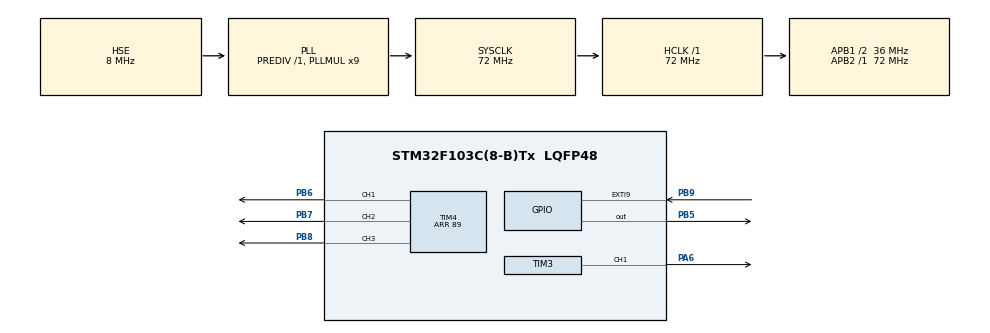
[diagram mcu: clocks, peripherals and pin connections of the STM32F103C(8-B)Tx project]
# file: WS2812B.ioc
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Dma.Request0=TIM4_CH3
Dma.Request1=TIM4_CH2
Dma.Request2=TIM4_CH1
Dma.TIM4_CH1.2.Direction=DMA_MEMORY_TO_PERIPH
Dma.TIM4_CH1.2.Instance=DMA1_Channel1
Dma.TIM4_CH1.2.MemDataAlignment=DMA_MDATAALIGN_HALFWORD
Dma.TIM4_CH1.2.MemInc=DMA_MINC_ENABLE
Dma.TIM4_CH1.2.Mode=DMA_NORMAL
Dma.TIM4_CH1.2.PeriphDataAlignment=DMA_PDATAALIGN_HALFWORD
Dma.TIM4_CH1.2.PeriphInc=DMA_PINC_DISABLE
Dma.TIM4_CH1.2.Priority=DMA_PRIORITY_HIGH
Dma.TIM4_CH2.1.Direction=DMA_MEMORY_TO_PERIPH
Dma.TIM4_CH2.1.Instance=DMA1_Channel4
Dma.TIM4_CH2.1.MemDataAlignment=DMA_MDATAALIGN_HALFWORD
Dma.TIM4_CH2.1.MemInc=DMA_MINC_ENABLE
Dma.TIM4_CH2.1.Mode=DMA_NORMAL
Dma.TIM4_CH2.1.PeriphDataAlignment=DMA_PDATAALIGN_HALFWORD
Dma.TIM4_CH2.1.PeriphInc=DMA_PINC_DISABLE
Dma.TIM4_CH2.1.Priority=DMA_PRIORITY_HIGH
Dma.TIM4_CH3.0.Direction=DMA_MEMORY_TO_PERIPH
Dma.TIM4_CH3.0.Instance=DMA1_Channel5
Dma.TIM4_CH3.0.MemDataAlignment=DMA_MDATAALIGN_HALFWORD
Dma.TIM4_CH3.0.MemInc=DMA_MINC_ENABLE
Dma.TIM4_CH3.0.Mode=DMA_NORMAL
Dma.TIM4_CH3.0.PeriphDataAlignment=DMA_PDATAALIGN_HALFWORD
Dma.TIM4_CH3.0.PeriphInc=DMA_PINC_DISABLE
Dma.TIM4_CH3.0.Priority=DMA_PRIORITY_HIGH
Mcu.Family=STM32F1
Mcu.Name=STM32F103C(8-B)Tx
Mcu.Package=LQFP48
NVIC.DMA1_Channel1_IRQn=true\:0\:0\:false\:false\:true\:false\:true
NVIC.DMA1_Channel4_IRQn=true\:0\:0\:false\:false\:true\:false\:true
NVIC.DMA1_Channel5_IRQn=true\:0\:0\:false\:false\:true\:false\:true
NVIC.EXTI9_5_IRQn=true\:0\:0\:false\:false\:true\:true\:true
NVIC.PriorityGroup=NVIC_PRIORITYGROUP_4
NVIC.TIM3_IRQn=true\:0\:0\:false\:false\:true\:true\:true
PA13.Mode=Serial_Wire
PA13.Signal=SYS_JTMS-SWDIO
PA14.Mode=Serial_Wire
PA14.Signal=SYS_JTCK-SWCLK
PA6.Signal=S_TIM3_CH1
PB5.GPIO_Speed=GPIO_SPEED_FREQ_LOW
PB5.Signal=GPIO_Output
PB6.GPIO_Speed=GPIO_SPEED_FREQ_HIGH
PB6.Signal=S_TIM4_CH1
PB7.GPIO_Speed=GPIO_SPEED_FREQ_HIGH
PB7.Signal=S_TIM4_CH2
PB8.GPIO_Speed=GPIO_SPEED_FREQ_HIGH
PB8.Signal=S_TIM4_CH3
PB9.GPIO_ModeDefaultEXTI=GPIO_MODE_IT_RISING
PB9.Signal=GPXTI9
PD0-OSC_IN.Mode=HSE-External-Oscillator
PD0-OSC_IN.Signal=RCC_OSC_IN
PD1-OSC_OUT.Mode=HSE-External-Oscillator
PD1-OSC_OUT.Signal=RCC_OSC_OUT
ProjectManager.HeapSize=0x200
ProjectManager.StackSize=0x400
ProjectManager.TargetToolchain=MDK-ARM V5
RCC.AHBFreq_Value=72000000
RCC.APB1CLKDivider=RCC_HCLK_DIV2
RCC.APB1Freq_Value=36000000
RCC.APB1TimFreq_Value=72000000
RCC.APB2Freq_Value=72000000
RCC.APB2TimFreq_Value=72000000
RCC.HCLKFreq_Value=72000000
RCC.PLLMUL=RCC_PLL_MUL9
RCC.PLLSourceVirtual=RCC_PLLSOURCE_HSE
RCC.SYSCLKFreq_VALUE=72000000
RCC.SYSCLKSource=RCC_SYSCLKSOURCE_PLLCLK
RCC.USBFreq_Value=72000000
SH.S_TIM3_CH1.0=TIM3_CH1,Output Compare1 CH1
SH.S_TIM4_CH1.0=TIM4_CH1,PWM Generation1 CH1
SH.S_TIM4_CH2.0=TIM4_CH2,PWM Generation2 CH2
SH.S_TIM4_CH3.0=TIM4_CH3,PWM Generation3 CH3
TIM3.Channel-Output\ Compare1\ CH1=TIM_CHANNEL_1
TIM3.Period=2000-1
TIM3.Prescaler=36000-1
TIM4.Channel-PWM\ Generation1\ CH1=TIM_CHANNEL_1
TIM4.Channel-PWM\ Generation2\ CH2=TIM_CHANNEL_2
TIM4.Channel-PWM\ Generation3\ CH3=TIM_CHANNEL_3
TIM4.Period=89
VP_TIM3_VS_ClockSourceINT.Mode=Internal
board=custom

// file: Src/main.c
/**
  ******************************************************************************
  * @file           : main.c
  * @brief          : Main program body
  ******************************************************************************
  ** This notice applies to any and all portions of this file
  * that are not between comment pairs USER CODE BEGIN and
  * USER CODE END. Other portions of this file, whether
  * inserted by the user or by software development tools
  * are owned by their respective copyright owners.
  *
  * COPYRIGHT(c) 2019 STMicroelectronics
  *
  * Redistribution and use in source and binary forms, with or without modification,
  * are permitted provided that the following conditions are met:
  *   1. Redistributions of source code must retain the above copyright notice,
  *      this list of conditions and the following disclaimer.
  *   2. Redistributions in binary form must reproduce the above copyright notice,
  *      this list of conditions and the following disclaimer in the documentation
  *      and/or other materials provided with the distribution.
  *   3. Neither the name of STMicroelectronics nor the names of its contributors
  *      may be used to endorse or promote products derived from this software
  *      without specific prior written permission.
  *
  * THIS SOFTWARE IS PROVIDED BY THE COPYRIGHT HOLDERS AND CONTRIBUTORS "AS IS"
  * AND ANY EXPRESS OR IMPLIED WARRANTIES, INCLUDING, BUT NOT LIMITED TO, THE
  * IMPLIED WARRANTIES OF MERCHANTABILITY AND FITNESS FOR A PARTICULAR PURPOSE ARE
  * DISCLAIMED. IN NO EVENT SHALL THE COPYRIGHT HOLDER OR CONTRIBUTORS BE LIABLE
  * FOR ANY DIRECT, INDIRECT, INCIDENTAL, SPECIAL, EXEMPLARY, OR CONSEQUENTIAL
  * DAMAGES (INCLUDING, BUT NOT LIMITED TO, PROCUREMENT OF SUBSTITUTE GOODS OR
  * SERVICES; LOSS OF USE, DATA, OR PROFITS; OR BUSINESS INTERRUPTION) HOWEVER
  * CAUSED AND ON ANY THEORY OF LIABILITY, WHETHER IN CONTRACT, STRICT LIABILITY,
  * OR TORT (INCLUDING NEGLIGENCE OR OTHERWISE) ARISING IN ANY WAY OUT OF THE USE
  * OF THIS SOFTWARE, EVEN IF ADVISED OF THE POSSIBILITY OF SUCH DAMAGE.
  *
  ******************************************************************************
  */
#include "main.h"
#include "stm32f1xx_hal.h"

/* USER CODE BEGIN Includes */
//#include "ws2812.h"

/* USER CODE END Includes */

TIM_HandleTypeDef htim3;
TIM_HandleTypeDef htim4;
DMA_HandleTypeDef hdma_tim4_ch3;
DMA_HandleTypeDef hdma_tim4_ch2;
DMA_HandleTypeDef hdma_tim4_ch1;

/* USER CODE BEGIN PV */
/* Private variables ---------------------------------------------------------*/
/* USER CODE END PV */

void SystemClock_Config(void);
static void MX_GPIO_Init(void);
static void MX_DMA_Init(void);
static void MX_TIM4_Init(void);
static void MX_TIM3_Init(void);
void HAL_TIM_MspPostInit(TIM_HandleTypeDef *htim);

/* USER CODE BEGIN PFP */
/* Private function prototypes -----------------------------------------------*/

/* USER CODE END PFP */

int main(void)
{

  /* MCU Configuration----------------------------------------------------------*/

  /* Reset of all peripherals, Initializes the Flash interface and the Systick. */
  HAL_Init();

  /* Configure the system clock */
  SystemClock_Config();

  /* Initialize all configured peripherals */
  MX_GPIO_Init();
  MX_DMA_Init();
  MX_TIM4_Init();
  MX_TIM3_Init();

  /* Infinite loop */
  while (1)
  {

  }

}

void SystemClock_Config(void)
{

  RCC_OscInitTypeDef RCC_OscInitStruct;
  RCC_ClkInitTypeDef RCC_ClkInitStruct;

    /**Initializes the CPU, AHB and APB busses clocks
    */
  RCC_OscInitStruct.OscillatorType = RCC_OSCILLATORTYPE_HSE;
  RCC_OscInitStruct.HSEState = RCC_HSE_ON;
  RCC_OscInitStruct.HSEPredivValue = RCC_HSE_PREDIV_DIV1;
  RCC_OscInitStruct.HSIState = RCC_HSI_ON;
  RCC_OscInitStruct.PLL.PLLState = RCC_PLL_ON;
  RCC_OscInitStruct.PLL.PLLSource = RCC_PLLSOURCE_HSE;
  RCC_OscInitStruct.PLL.PLLMUL = RCC_PLL_MUL9;
  if (HAL_RCC_OscConfig(&RCC_OscInitStruct) != HAL_OK)
  {
    _Error_Handler(__FILE__, __LINE__);
  }

    /**Initializes the CPU, AHB and APB busses clocks
    */
  RCC_ClkInitStruct.ClockType = RCC_CLOCKTYPE_HCLK|RCC_CLOCKTYPE_SYSCLK
                              |RCC_CLOCKTYPE_PCLK1|RCC_CLOCKTYPE_PCLK2;
  RCC_ClkInitStruct.SYSCLKSource = RCC_SYSCLKSOURCE_PLLCLK;
  RCC_ClkInitStruct.AHBCLKDivider = RCC_SYSCLK_DIV1;
  RCC_ClkInitStruct.APB1CLKDivider = RCC_HCLK_DIV2;
  RCC_ClkInitStruct.APB2CLKDivider = RCC_HCLK_DIV1;

  if (HAL_RCC_ClockConfig(&RCC_ClkInitStruct, FLASH_LATENCY_2) != HAL_OK)
  {
    _Error_Handler(__FILE__, __LINE__);
  }

    /**Configure the Systick interrupt time
    */
  HAL_SYSTICK_Config(HAL_RCC_GetHCLKFreq()/1000);

    /**Configure the Systick
    */
  HAL_SYSTICK_CLKSourceConfig(SYSTICK_CLKSOURCE_HCLK);

  /* SysTick_IRQn interrupt configuration */
  HAL_NVIC_SetPriority(SysTick_IRQn, 0, 0);
}

/* TIM3 init function */
static void MX_TIM3_Init(void)
{

  TIM_ClockConfigTypeDef sClockSourceConfig;
  TIM_MasterConfigTypeDef sMasterConfig;
  TIM_OC_InitTypeDef sConfigOC;

  htim3.Instance = TIM3;
  htim3.Init.Prescaler = 36000-1;
  htim3.Init.CounterMode = TIM_COUNTERMODE_UP;
  htim3.Init.Period = 2000-1;
  htim3.Init.ClockDivision = TIM_CLOCKDIVISION_DIV1;
  htim3.Init.AutoReloadPreload = TIM_AUTORELOAD_PRELOAD_DISABLE;
  if (HAL_TIM_Base_Init(&htim3) != HAL_OK)
  {
    _Error_Handler(__FILE__, __LINE__);
  }

  sClockSourceConfig.ClockSource = TIM_CLOCKSOURCE_INTERNAL;
  if (HAL_TIM_ConfigClockSource(&htim3, &sClockSourceConfig) != HAL_OK)
  {
    _Error_Handler(__FILE__, __LINE__);
  }

  if (HAL_TIM_OC_Init(&htim3) != HAL_OK)
  {
    _Error_Handler(__FILE__, __LINE__);
  }

  sMasterConfig.MasterOutputTrigger = TIM_TRGO_RESET;
  sMasterConfig.MasterSlaveMode = TIM_MASTERSLAVEMODE_DISABLE;
  if (HAL_TIMEx_MasterConfigSynchronization(&htim3, &sMasterConfig) != HAL_OK)
  {
    _Error_Handler(__FILE__, __LINE__);
  }

  sConfigOC.OCMode = TIM_OCMODE_TIMING;
  sConfigOC.Pulse = 0;
  sConfigOC.OCPolarity = TIM_OCPOLARITY_HIGH;
  sConfigOC.OCFastMode = TIM_OCFAST_DISABLE;
  if (HAL_TIM_OC_ConfigChannel(&htim3, &sConfigOC, TIM_CHANNEL_1) != HAL_OK)
  {
    _Error_Handler(__FILE__, __LINE__);
  }

  HAL_TIM_MspPostInit(&htim3);

}

/* TIM4 init function */
static void MX_TIM4_Init(void)
{

  TIM_MasterConfigTypeDef sMasterConfig;
  TIM_OC_InitTypeDef sConfigOC;

  htim4.Instance = TIM4;
  htim4.Init.Prescaler = 0;
  htim4.Init.CounterMode = TIM_COUNTERMODE_UP;
  htim4.Init.Period = 89;
  htim4.Init.ClockDivision = TIM_CLOCKDIVISION_DIV1;
  htim4.Init.AutoReloadPreload = TIM_AUTORELOAD_PRELOAD_DISABLE;
  if (HAL_TIM_PWM_Init(&htim4) != HAL_OK)
  {
    _Error_Handler(__FILE__, __LINE__);
  }

  sMasterConfig.MasterOutputTrigger = TIM_TRGO_RESET;
  sMasterConfig.MasterSlaveMode = TIM_MASTERSLAVEMODE_DISABLE;
  if (HAL_TIMEx_MasterConfigSynchronization(&htim4, &sMasterConfig) != HAL_OK)
  {
    _Error_Handler(__FILE__, __LINE__);
  }

  sConfigOC.OCMode = TIM_OCMODE_PWM1;
  sConfigOC.Pulse = 0;
  sConfigOC.OCPolarity = TIM_OCPOLARITY_HIGH;
  sConfigOC.OCFastMode = TIM_OCFAST_DISABLE;
  if (HAL_TIM_PWM_ConfigChannel(&htim4, &sConfigOC, TIM_CHANNEL_1) != HAL_OK)
  {
    _Error_Handler(__FILE__, __LINE__);
  }

  if (HAL_TIM_PWM_ConfigChannel(&htim4, &sConfigOC, TIM_CHANNEL_2) != HAL_OK)
  {
    _Error_Handler(__FILE__, __LINE__);
  }

  if (HAL_TIM_PWM_ConfigChannel(&htim4, &sConfigOC, TIM_CHANNEL_3) != HAL_OK)
  {
    _Error_Handler(__FILE__, __LINE__);
  }

  HAL_TIM_MspPostInit(&htim4);

}

static void MX_DMA_Init(void)
{
  /* DMA controller clock enable */
  __HAL_RCC_DMA1_CLK_ENABLE();

  /* DMA interrupt init */
  /* DMA1_Channel1_IRQn interrupt configuration */
  HAL_NVIC_SetPriority(DMA1_Channel1_IRQn,2,0);
  HAL_NVIC_EnableIRQ(DMA1_Channel1_IRQn);
  /* DMA1_Channel4_IRQn interrupt configuration */
  HAL_NVIC_SetPriority(DMA1_Channel4_IRQn, 2, 0);
  HAL_NVIC_EnableIRQ(DMA1_Channel4_IRQn);
  /* DMA1_Channel5_IRQn interrupt configuration */
  HAL_NVIC_SetPriority(DMA1_Channel5_IRQn, 2, 0);
  HAL_NVIC_EnableIRQ(DMA1_Channel5_IRQn);

}

/** Configure pins as
        * Analog
        * Input
        * Output
        * EVENT_OUT
        * EXTI
*/
static void MX_GPIO_Init(void)
{

  GPIO_InitTypeDef GPIO_InitStruct;

  /* GPIO Ports Clock Enable */
  __HAL_RCC_GPIOD_CLK_ENABLE();
  __HAL_RCC_GPIOA_CLK_ENABLE();
  __HAL_RCC_GPIOB_CLK_ENABLE();

  /*Configure GPIO pin Output Level */
  HAL_GPIO_WritePin(GPIOB, GPIO_PIN_5, GPIO_PIN_RESET);

  /*Configure GPIO pin : PB5 */
  GPIO_InitStruct.Pin = GPIO_PIN_5;
  GPIO_InitStruct.Mode = GPIO_MODE_OUTPUT_PP;
  GPIO_InitStruct.Pull = GPIO_NOPULL;
  GPIO_InitStruct.Speed = GPIO_SPEED_FREQ_LOW;
  HAL_GPIO_Init(GPIOB, &GPIO_InitStruct);

  /*Configure GPIO pin : PB9 */
  GPIO_InitStruct.Pin = GPIO_PIN_9;
  GPIO_InitStruct.Mode = GPIO_MODE_IT_RISING;
  GPIO_InitStruct.Pull = GPIO_NOPULL;
  HAL_GPIO_Init(GPIOB, &GPIO_InitStruct);

  /* EXTI interrupt init*/
  HAL_NVIC_SetPriority(EXTI9_5_IRQn, 0, 0);
  HAL_NVIC_EnableIRQ(EXTI9_5_IRQn);

}

void _Error_Handler(char *file, int line)
{
  while(1)
  {
  }
}

/************************ (C) COPYRIGHT STMicroelectronics *****END OF FILE****/
